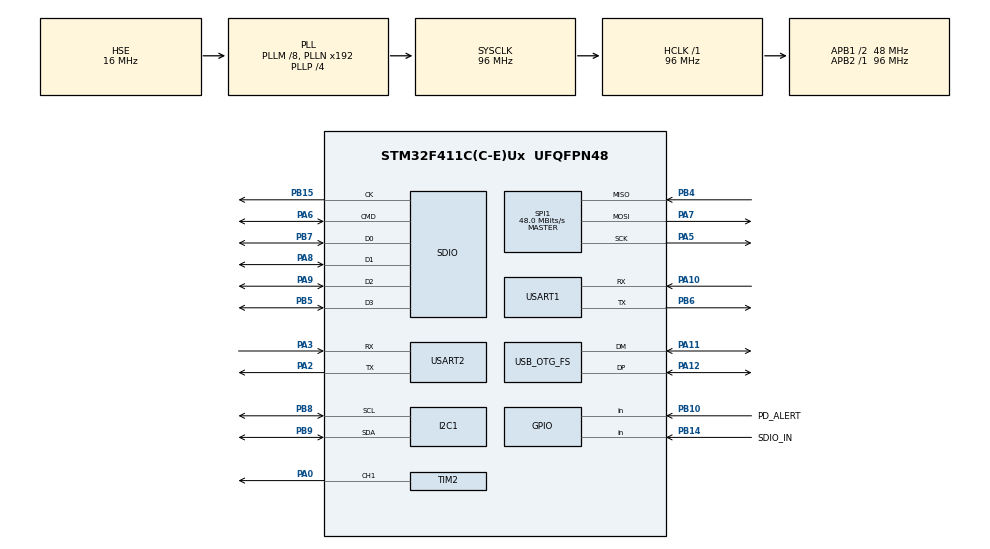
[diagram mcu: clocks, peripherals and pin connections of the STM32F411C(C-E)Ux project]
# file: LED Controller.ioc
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Dma.Request0=TIM2_CH1
Dma.TIM2_CH1.0.Direction=DMA_MEMORY_TO_PERIPH
Dma.TIM2_CH1.0.FIFOMode=DMA_FIFOMODE_DISABLE
Dma.TIM2_CH1.0.Instance=DMA1_Stream5
Dma.TIM2_CH1.0.MemDataAlignment=DMA_MDATAALIGN_WORD
Dma.TIM2_CH1.0.MemInc=DMA_MINC_ENABLE
Dma.TIM2_CH1.0.Mode=DMA_NORMAL
Dma.TIM2_CH1.0.PeriphDataAlignment=DMA_PDATAALIGN_WORD
Dma.TIM2_CH1.0.PeriphInc=DMA_PINC_DISABLE
Dma.TIM2_CH1.0.Priority=DMA_PRIORITY_MEDIUM
FATFS.BSP.number=1
FATFS0.BSP.STBoard=false
FATFS0.BSP.api=Unknown
FATFS0.BSP.i2caddr=0
FATFS0.BSP.instance=PB14
FATFS0.BSP.ip=GPIO
FATFS0.BSP.mode=Input
FATFS0.BSP.name=Detect_SDIO
FATFS0.BSP.solution=PB14
FREERTOS.Tasks01=defaultTask,24,128,StartDefaultTask,Default,NULL,Dynamic,NULL,NULL
FREERTOS.configUSE_NEWLIB_REENTRANT=1
Mcu.Family=STM32F4
Mcu.Name=STM32F411C(C-E)Ux
Mcu.Package=UFQFPN48
NVIC.DMA1_Stream5_IRQn=true\:5\:0\:false\:false\:true\:true\:false\:true
NVIC.OTG_FS_IRQn=true\:5\:0\:false\:false\:true\:true\:false\:true
NVIC.PriorityGroup=NVIC_PRIORITYGROUP_4
NVIC.TIM1_UP_TIM10_IRQn=true\:15\:0\:false\:false\:true\:false\:false\:true
NVIC.TimeBase=TIM1_UP_TIM10_IRQn
NVIC.TimeBaseIP=TIM1
PA0-WKUP.Signal=S_TIM2_CH1_ETR
PA10.Mode=Asynchronous
PA10.Signal=USART1_RX
PA11.Mode=Device_Only
PA11.Signal=USB_OTG_FS_DM
PA12.Mode=Device_Only
PA12.Signal=USB_OTG_FS_DP
PA13.Mode=JTAG_4_pins
PA13.Signal=SYS_JTMS-SWDIO
PA14.Mode=JTAG_4_pins
PA14.Signal=SYS_JTCK-SWCLK
PA15.Mode=JTAG_4_pins
PA15.Signal=SYS_JTDI
PA2.Mode=Asynchronous
PA2.Signal=USART2_TX
PA3.Mode=Asynchronous
PA3.Signal=USART2_RX
PA5.Mode=Full_Duplex_Master
PA5.Signal=SPI1_SCK
PA6.Mode=SD_4_bits_Wide_bus
PA6.Signal=SDIO_CMD
PA7.Mode=Full_Duplex_Master
PA7.Signal=SPI1_MOSI
PA8.Mode=SD_4_bits_Wide_bus
PA8.Signal=SDIO_D1
PA9.Mode=SD_4_bits_Wide_bus
PA9.Signal=SDIO_D2
PB10.GPIO_Label=PD_ALERT
PB10.Signal=GPIO_Input
PB14.GPIO_Label=SDIO_IN
PB14.GPIO_PuPd=GPIO_PULLUP
PB14.Signal=GPIO_Input
PB15.Mode=SD_4_bits_Wide_bus
PB15.Signal=SDIO_CK
PB3.Mode=JTAG_4_pins
PB3.Signal=SYS_JTDO-SWO
PB4.Mode=Full_Duplex_Master
PB4.Signal=SPI1_MISO
PB5.Mode=SD_4_bits_Wide_bus
PB5.Signal=SDIO_D3
PB6.Mode=Asynchronous
PB6.Signal=USART1_TX
PB7.Mode=SD_4_bits_Wide_bus
PB7.Signal=SDIO_D0
PB8.Mode=I2C
PB8.Signal=I2C1_SCL
PB9.Mode=I2C
PB9.Signal=I2C1_SDA
PH0\ -\ OSC_IN.Mode=HSE-External-Oscillator
PH0\ -\ OSC_IN.Signal=RCC_OSC_IN
PH1\ -\ OSC_OUT.Mode=HSE-External-Oscillator
PH1\ -\ OSC_OUT.Signal=RCC_OSC_OUT
ProjectManager.HeapSize=0x200
ProjectManager.StackSize=0x400
ProjectManager.TargetToolchain=STM32CubeIDE
RCC.48MHZClocksFreq_Value=48000000
RCC.AHBFreq_Value=96000000
RCC.APB1CLKDivider=RCC_HCLK_DIV2
RCC.APB1Freq_Value=48000000
RCC.APB1TimFreq_Value=96000000
RCC.APB2Freq_Value=96000000
RCC.APB2TimFreq_Value=96000000
RCC.CortexFreq_Value=96000000
RCC.HCLKFreq_Value=96000000
RCC.HSE_VALUE=16000000
RCC.HSI_VALUE=16000000
RCC.LSE_VALUE=32768
RCC.PLLM=8
RCC.PLLP=RCC_PLLP_DIV4
RCC.PLLQ=8
RCC.SYSCLKFreq_VALUE=96000000
RCC.SYSCLKSource=RCC_SYSCLKSOURCE_PLLCLK
RCC.VCOOutputFreq_Value=384000000
SH.S_TIM2_CH1_ETR.0=TIM2_CH1,PWM Generation1 CH1
SPI1.BaudRatePrescaler=SPI_BAUDRATEPRESCALER_2
SPI1.CalculateBaudRate=48.0 MBits/s
SPI1.Direction=SPI_DIRECTION_2LINES
SPI1.Mode=SPI_MODE_MASTER
SPI1.VirtualType=VM_MASTER
TIM2.Channel-PWM\ Generation1\ CH1=TIM_CHANNEL_1
USART1.VirtualMode=VM_ASYNC
USART2.VirtualMode=VM_ASYNC
USB_DEVICE.CLASS_NAME_FS=MSC
USB_DEVICE.MANUFACTURER_STRING=Charlie Electronics
USB_DEVICE.PRODUCT_STRING_MSC_FS=LED Controller
USB_DEVICE.VirtualMode=Msc
USB_DEVICE.VirtualModeFS=Msc_FS
USB_OTG_FS.VirtualMode=Device_Only
VP_CRC_VS_CRC.Mode=CRC_Activate
VP_FATFS_VS_SDIO.Mode=SDIO
VP_FREERTOS_VS_CMSIS_V2.Mode=CMSIS_V2
VP_IWDG_VS_IWDG.Mode=IWDG_Activate
VP_MBEDTLS_VS_MBEDTLS.Mode=Enabled
VP_SYS_VS_tim1.Mode=TIM1
VP_TIM2_VS_ClockSourceINT.Mode=Internal
VP_TIM2_VS_ClockSourceITR.Mode=TriggerSource_ITR0
VP_USB_DEVICE_VS_USB_DEVICE_MSC_FS.Mode=MSC_FS
board=custom

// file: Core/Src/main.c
/* USER CODE BEGIN Header */
/**
  ******************************************************************************
  * @file           : main.c
  * @brief          : Main program body
  ******************************************************************************
  * @attention
  *
  * Copyright (c) 2022 STMicroelectronics.
  * All rights reserved.
  *
  * This software is licensed under terms that can be found in the LICENSE file
  * in the root directory of this software component.
  * If no LICENSE file comes with this software, it is provided AS-IS.
  *
  ******************************************************************************
  */
/* USER CODE END Header */
#include "main.h"
#include "cmsis_os.h"
#include "fatfs.h"
#include "mbedtls.h"
#include "usb_device.h"

/* USER CODE BEGIN Includes */
#include "error_handler.h"
/* USER CODE END Includes */

CRC_HandleTypeDef hcrc;

I2C_HandleTypeDef hi2c1;

IWDG_HandleTypeDef hiwdg;

SD_HandleTypeDef hsd;

SPI_HandleTypeDef hspi1;

TIM_HandleTypeDef htim2;
DMA_HandleTypeDef hdma_tim2_ch1;

UART_HandleTypeDef huart1;
UART_HandleTypeDef huart2;

/* Definitions for defaultTask */
osThreadId_t defaultTaskHandle;
const osThreadAttr_t defaultTask_attributes = {
  .name = "defaultTask",
  .stack_size = 128 * 4,
  .priority = (osPriority_t) osPriorityNormal,
};

void SystemClock_Config(void);
static void MX_GPIO_Init(void);
static void MX_CRC_Init(void);
static void MX_SDIO_SD_Init(void);
static void MX_I2C1_Init(void);
static void MX_IWDG_Init(void);
static void MX_SPI1_Init(void);
static void MX_USART1_UART_Init(void);
static void MX_USART2_UART_Init(void);
static void MX_DMA_Init(void);
static void MX_TIM2_Init(void);
void StartDefaultTask(void *argument);

int main(void)
{

  /* MCU Configuration--------------------------------------------------------*/

  /* Reset of all peripherals, Initializes the Flash interface and the Systick. */
  HAL_Init();

  /* Configure the system clock */
  SystemClock_Config();

  /* Initialize all configured peripherals */
  MX_GPIO_Init();
  MX_CRC_Init();
  MX_SDIO_SD_Init();
  MX_FATFS_Init();
  MX_I2C1_Init();
  MX_IWDG_Init();
  MX_SPI1_Init();
  MX_USART1_UART_Init();
  MX_USART2_UART_Init();
  MX_MBEDTLS_Init();
  MX_DMA_Init();
  MX_TIM2_Init();

  /* Init scheduler */
  osKernelInitialize();

  /* Create the thread(s) */
  /* creation of defaultTask */
  defaultTaskHandle = osThreadNew(StartDefaultTask, NULL, &defaultTask_attributes);

  /* Start scheduler */
  osKernelStart();

  /* We should never get here as control is now taken by the scheduler */
  /* Infinite loop */
  while (1)
  {

  }
}

void SystemClock_Config(void)
{
  RCC_OscInitTypeDef RCC_OscInitStruct = {0};
  RCC_ClkInitTypeDef RCC_ClkInitStruct = {0};

  /** Configure the main internal regulator output voltage
  */
  __HAL_RCC_PWR_CLK_ENABLE();
  __HAL_PWR_VOLTAGESCALING_CONFIG(PWR_REGULATOR_VOLTAGE_SCALE1);
  /** Initializes the RCC Oscillators according to the specified parameters
  * in the RCC_OscInitTypeDef structure.
  */
  RCC_OscInitStruct.OscillatorType = RCC_OSCILLATORTYPE_LSI|RCC_OSCILLATORTYPE_HSE;
  RCC_OscInitStruct.HSEState = RCC_HSE_ON;
  RCC_OscInitStruct.LSIState = RCC_LSI_ON;
  RCC_OscInitStruct.PLL.PLLState = RCC_PLL_ON;
  RCC_OscInitStruct.PLL.PLLSource = RCC_PLLSOURCE_HSE;
  RCC_OscInitStruct.PLL.PLLM = 8;
  RCC_OscInitStruct.PLL.PLLN = 192;
  RCC_OscInitStruct.PLL.PLLP = RCC_PLLP_DIV4;
  RCC_OscInitStruct.PLL.PLLQ = 8;
  if (HAL_RCC_OscConfig(&RCC_OscInitStruct) != HAL_OK)
  {
    Error_Handler();
  }
  /** Initializes the CPU, AHB and APB buses clocks
  */
  RCC_ClkInitStruct.ClockType = RCC_CLOCKTYPE_HCLK|RCC_CLOCKTYPE_SYSCLK
                              |RCC_CLOCKTYPE_PCLK1|RCC_CLOCKTYPE_PCLK2;
  RCC_ClkInitStruct.SYSCLKSource = RCC_SYSCLKSOURCE_PLLCLK;
  RCC_ClkInitStruct.AHBCLKDivider = RCC_SYSCLK_DIV1;
  RCC_ClkInitStruct.APB1CLKDivider = RCC_HCLK_DIV2;
  RCC_ClkInitStruct.APB2CLKDivider = RCC_HCLK_DIV1;

  if (HAL_RCC_ClockConfig(&RCC_ClkInitStruct, FLASH_LATENCY_3) != HAL_OK)
  {
    Error_Handler();
  }
}

static void MX_CRC_Init(void)
{

  hcrc.Instance = CRC;
  if (HAL_CRC_Init(&hcrc) != HAL_OK)
  {
    Error_Handler();
  }

}

static void MX_I2C1_Init(void)
{

  hi2c1.Instance = I2C1;
  hi2c1.Init.ClockSpeed = 100000;
  hi2c1.Init.DutyCycle = I2C_DUTYCYCLE_2;
  hi2c1.Init.OwnAddress1 = 0;
  hi2c1.Init.AddressingMode = I2C_ADDRESSINGMODE_7BIT;
  hi2c1.Init.DualAddressMode = I2C_DUALADDRESS_DISABLE;
  hi2c1.Init.OwnAddress2 = 0;
  hi2c1.Init.GeneralCallMode = I2C_GENERALCALL_DISABLE;
  hi2c1.Init.NoStretchMode = I2C_NOSTRETCH_DISABLE;
  if (HAL_I2C_Init(&hi2c1) != HAL_OK)
  {
    Error_Handler();
  }

}

static void MX_IWDG_Init(void)
{

  hiwdg.Instance = IWDG;
  hiwdg.Init.Prescaler = IWDG_PRESCALER_4;
  hiwdg.Init.Reload = 4095;
  if (HAL_IWDG_Init(&hiwdg) != HAL_OK)
  {
    Error_Handler();
  }

}

static void MX_SDIO_SD_Init(void)
{

  hsd.Instance = SDIO;
  hsd.Init.ClockEdge = SDIO_CLOCK_EDGE_RISING;
  hsd.Init.ClockBypass = SDIO_CLOCK_BYPASS_DISABLE;
  hsd.Init.ClockPowerSave = SDIO_CLOCK_POWER_SAVE_DISABLE;
  hsd.Init.BusWide = SDIO_BUS_WIDE_1B;
  hsd.Init.HardwareFlowControl = SDIO_HARDWARE_FLOW_CONTROL_DISABLE;
  hsd.Init.ClockDiv = 0;

}

static void MX_SPI1_Init(void)
{

  /* SPI1 parameter configuration*/
  hspi1.Instance = SPI1;
  hspi1.Init.Mode = SPI_MODE_MASTER;
  hspi1.Init.Direction = SPI_DIRECTION_2LINES;
  hspi1.Init.DataSize = SPI_DATASIZE_8BIT;
  hspi1.Init.CLKPolarity = SPI_POLARITY_LOW;
  hspi1.Init.CLKPhase = SPI_PHASE_1EDGE;
  hspi1.Init.NSS = SPI_NSS_SOFT;
  hspi1.Init.BaudRatePrescaler = SPI_BAUDRATEPRESCALER_2;
  hspi1.Init.FirstBit = SPI_FIRSTBIT_MSB;
  hspi1.Init.TIMode = SPI_TIMODE_DISABLE;
  hspi1.Init.CRCCalculation = SPI_CRCCALCULATION_DISABLE;
  hspi1.Init.CRCPolynomial = 10;
  if (HAL_SPI_Init(&hspi1) != HAL_OK)
  {
    Error_Handler();
  }

}

static void MX_TIM2_Init(void)
{

  TIM_ClockConfigTypeDef sClockSourceConfig = {0};
  TIM_SlaveConfigTypeDef sSlaveConfig = {0};
  TIM_MasterConfigTypeDef sMasterConfig = {0};
  TIM_OC_InitTypeDef sConfigOC = {0};

  htim2.Instance = TIM2;
  htim2.Init.Prescaler = 0;
  htim2.Init.CounterMode = TIM_COUNTERMODE_UP;
  htim2.Init.Period = 4294967295;
  htim2.Init.ClockDivision = TIM_CLOCKDIVISION_DIV1;
  htim2.Init.AutoReloadPreload = TIM_AUTORELOAD_PRELOAD_DISABLE;
  if (HAL_TIM_Base_Init(&htim2) != HAL_OK)
  {
    Error_Handler();
  }
  sClockSourceConfig.ClockSource = TIM_CLOCKSOURCE_INTERNAL;
  if (HAL_TIM_ConfigClockSource(&htim2, &sClockSourceConfig) != HAL_OK)
  {
    Error_Handler();
  }
  if (HAL_TIM_PWM_Init(&htim2) != HAL_OK)
  {
    Error_Handler();
  }
  sSlaveConfig.SlaveMode = TIM_SLAVEMODE_DISABLE;
  sSlaveConfig.InputTrigger = TIM_TS_ITR0;
  if (HAL_TIM_SlaveConfigSynchro(&htim2, &sSlaveConfig) != HAL_OK)
  {
    Error_Handler();
  }
  sMasterConfig.MasterOutputTrigger = TIM_TRGO_RESET;
  sMasterConfig.MasterSlaveMode = TIM_MASTERSLAVEMODE_DISABLE;
  if (HAL_TIMEx_MasterConfigSynchronization(&htim2, &sMasterConfig) != HAL_OK)
  {
    Error_Handler();
  }
  sConfigOC.OCMode = TIM_OCMODE_PWM1;
  sConfigOC.Pulse = 0;
  sConfigOC.OCPolarity = TIM_OCPOLARITY_HIGH;
  sConfigOC.OCFastMode = TIM_OCFAST_DISABLE;
  if (HAL_TIM_PWM_ConfigChannel(&htim2, &sConfigOC, TIM_CHANNEL_1) != HAL_OK)
  {
    Error_Handler();
  }
  HAL_TIM_MspPostInit(&htim2);

}

static void MX_USART1_UART_Init(void)
{

  huart1.Instance = USART1;
  huart1.Init.BaudRate = 115200;
  huart1.Init.WordLength = UART_WORDLENGTH_8B;
  huart1.Init.StopBits = UART_STOPBITS_1;
  huart1.Init.Parity = UART_PARITY_NONE;
  huart1.Init.Mode = UART_MODE_TX_RX;
  huart1.Init.HwFlowCtl = UART_HWCONTROL_NONE;
  huart1.Init.OverSampling = UART_OVERSAMPLING_16;
  if (HAL_UART_Init(&huart1) != HAL_OK)
  {
    Error_Handler();
  }

}

static void MX_USART2_UART_Init(void)
{

  huart2.Instance = USART2;
  huart2.Init.BaudRate = 115200;
  huart2.Init.WordLength = UART_WORDLENGTH_8B;
  huart2.Init.StopBits = UART_STOPBITS_1;
  huart2.Init.Parity = UART_PARITY_NONE;
  huart2.Init.Mode = UART_MODE_TX_RX;
  huart2.Init.HwFlowCtl = UART_HWCONTROL_NONE;
  huart2.Init.OverSampling = UART_OVERSAMPLING_16;
  if (HAL_UART_Init(&huart2) != HAL_OK)
  {
    Error_Handler();
  }

}

static void MX_DMA_Init(void)
{

  /* DMA controller clock enable */
  __HAL_RCC_DMA1_CLK_ENABLE();

  /* DMA interrupt init */
  /* DMA1_Stream5_IRQn interrupt configuration */
  HAL_NVIC_SetPriority(DMA1_Stream5_IRQn, 5, 0);
  HAL_NVIC_EnableIRQ(DMA1_Stream5_IRQn);

}

static void MX_GPIO_Init(void)
{
  GPIO_InitTypeDef GPIO_InitStruct = {0};

  /* GPIO Ports Clock Enable */
  __HAL_RCC_GPIOH_CLK_ENABLE();
  __HAL_RCC_GPIOA_CLK_ENABLE();
  __HAL_RCC_GPIOB_CLK_ENABLE();

  /*Configure GPIO pin : PD_ALERT_Pin */
  GPIO_InitStruct.Pin = PD_ALERT_Pin;
  GPIO_InitStruct.Mode = GPIO_MODE_INPUT;
  GPIO_InitStruct.Pull = GPIO_NOPULL;
  HAL_GPIO_Init(PD_ALERT_GPIO_Port, &GPIO_InitStruct);

  /*Configure GPIO pin : SDIO_IN_Pin */
  GPIO_InitStruct.Pin = SDIO_IN_Pin;
  GPIO_InitStruct.Mode = GPIO_MODE_INPUT;
  GPIO_InitStruct.Pull = GPIO_PULLUP;
  HAL_GPIO_Init(SDIO_IN_GPIO_Port, &GPIO_InitStruct);

}

void StartDefaultTask(void *argument)
{
  /* init code for USB_DEVICE */
  MX_USB_DEVICE_Init();
  for(;;)
  {
    osDelay(1);
  }
}

void HAL_TIM_PeriodElapsedCallback(TIM_HandleTypeDef *htim)
{
  if (htim->Instance == TIM1) {
    HAL_IncTick();
  }
}

void Error_Handler(void)
{
  __disable_irq();
  while (1)
  {
  }
}
